VERSION ""

NS_ :

BS_:

BU_: EngineECU TransmissionECU DisplayECU

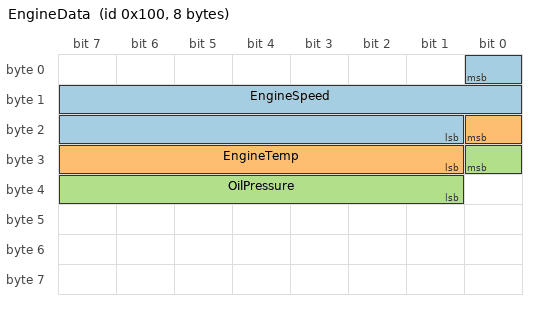
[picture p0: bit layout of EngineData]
BO_ 256 EngineData: 8 EngineECU
 SG_ EngineSpeed : 0|16@0+ (1,0) [0|8000] "rpm" DisplayECU
 SG_ EngineTemp : 16|8@0+ (1,-40) [-40|215] "degC" DisplayECU
 SG_ OilPressure : 24|8@0+ (0.1,0) [0|25] "bar" DisplayECU

BO_ 512 TransmissionData: 4 TransmissionECU
 SG_ GearPos : 7|4@0+ (1,0) [0|15] "" DisplayECU
 SG_ VehicleSpeed : 3|12@0+ (0.1,0) [0|400] "km/h" DisplayECU

BO_ 768 AmbientData: 2 SensorECU
 SG_ OutsideTemp : 7|8@0+ (1,-40) [-40|100] "degC" DisplayECU
 SG_ Humidity : 15|8@0+ (0.5,0) [0|100] "%" DisplayECU

CM_ BO_ 256 "Engine status information";
CM_ SG_ 256 EngineSpeed "Current engine rotations per minute";
CM_ BO_ 512 "Transmission status and vehicle speed";
CM_ BO_ 768 "Environment sensor data";

VAL_ 512 GearPos 0 "Neutral" 1 "First" 2 "Second" 3 "Third" 4 "Fourth" 5 "Fifth" 6 "Sixth" 7 "Reverse" 15 "Error" ;
